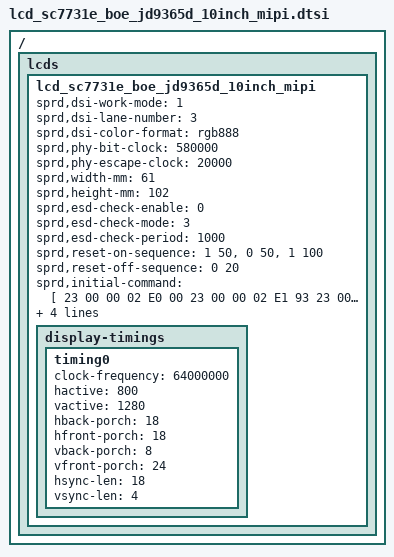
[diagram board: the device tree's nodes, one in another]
/ { lcds {
	lcd_sc7731e_boe_jd9365d_10inch_mipi: lcd_sc7731e_boe_jd9365d_10inch_mipi {

		sprd,dsi-work-mode = <1>;
		sprd,dsi-lane-number = <3>;
		sprd,dsi-color-format = "rgb888";

		sprd,phy-bit-clock = <580000>;
		sprd,phy-escape-clock = <20000>;

		sprd,width-mm = <61>;
		sprd,height-mm = <102>;

		sprd,esd-check-enable = <0>;
		sprd,esd-check-mode = <3>;
		sprd,esd-check-period = <1000>;
		/*sprd,esd-check-register = <0x0A>;*/
		/*sprd,esd-check-value = <0x9C>;*/

		sprd,reset-on-sequence = <1 50>, <0 50>, <1 100>;
		sprd,reset-off-sequence = <0 20>;

		sprd,initial-command = [
	 23 00 00 02 E0 00
		//--- PASSWORD  ----//
		 23 00 00 02 E1 93
		 23 00 00 02 E2 65
		 23 00 00 02 E3 F8
		 23 00 00 02 80 02// 03:4-LANE; 02:3-LANE; 01:2-LANE

		//--- Page1  ----//
		 23 00 00 02 E0 01

		// 23 00 00 02 4A 30 //bist mode

		//Set VCOM
		 23 00 00 02 00 00
		 23 00 00 02 01 66
		 23 00 00 02 0E 01	//LEDON output VCSW2
		//Set Gamma Power VGMPVGMNVGSPVGSN
		 23 00 00 02 17 00
		 23 00 00 02 18 AF//4.3V
		 23 00 00 02 19 01//0.3V
		 23 00 00 02 1A 00//
		 23 00 00 02 1B AF//4.3V
		 23 00 00 02 1C 01//0.3V               
		//Set Gate Power
		 23 00 00 02 1F 3E     //VGH_R  = 15V                       
		 23 00 00 02 20 28     //VGL_R  = -12V                      
		 23 00 00 02 21 28     //VGL_R2 = -12V                      
		 23 00 00 02 22 7E     //PA[6]=1 PA[5]=1 PA[4]=1 PA[0]=0 
		//SETPANEL
		 23 00 00 02 35 26	//ASP=0110
		//SETPANEL
		 23 00 00 02 37 09	//SS=1BGR=1
		//SET RGBCYC
		 23 00 00 02 38 04	//JDT=100 column inversion
		 23 00 00 02 39 00	//RGB_N_EQ1 12
		 23 00 00 02 3A 01	//RGB_N_EQ2 18
		 23 00 00 02 3C 7C	//SET EQ3 for TE_H
		 23 00 00 02 3D FF	//SET CHGEN_ON 
		 23 00 00 02 3E FF	//SET CHGEN_OFF 
		 23 00 00 02 3F 7F	//SET CHGEN_OFF2
		//Set TCON
		 23 00 00 02 40 06	//RSO=800 RGB
		 23 00 00 02 41 A0	//LN=640->1280 line
		 23 00 00 02 42 81	//SLT
		 23 00 00 02 43 08	//VFP=8
		 23 00 00 02 44 0B	//VBP=12
		 23 00 00 02 45 28  //HBP=40
		//--- power voltage  ----//
		 23 00 00 02 55 01	//DCDCM=0001 JD PWR_IC
		 23 00 00 02 56 01
		 23 00 00 02 57 69
		 23 00 00 02 58 0A
		 23 00 00 02 59 0A	//VCL = -2.5V
		 23 00 00 02 5A 29	//VGH = 15.2V
		 23 00 00 02 5B 15	//VGL = -11.2V
		//--- Gamma  ----//
		 23 00 00 02 5D 7C              
		 23 00 00 02 5E 65      
		 23 00 00 02 5F 55    
		 23 00 00 02 60 47    
		 23 00 00 02 61 43    
		 23 00 00 02 62 32    
		 23 00 00 02 63 34    
		 23 00 00 02 64 1C    
		 23 00 00 02 65 33    
		 23 00 00 02 66 31    
		 23 00 00 02 67 30    
		 23 00 00 02 68 4E    
		 23 00 00 02 69 3C    
		 23 00 00 02 6A 44    
		 23 00 00 02 6B 35    
		 23 00 00 02 6C 31    
		 23 00 00 02 6D 23    
		 23 00 00 02 6E 11    
		 23 00 00 02 6F 00    
		 23 00 00 02 70 7C    
		 23 00 00 02 71 65    
		 23 00 00 02 72 55    
		 23 00 00 02 73 47    
		 23 00 00 02 74 43    
		 23 00 00 02 75 32    
		 23 00 00 02 76 34    
		 23 00 00 02 77 1C    
		 23 00 00 02 78 33    
		 23 00 00 02 79 31    
		 23 00 00 02 7A 30    
		 23 00 00 02 7B 4E    
		 23 00 00 02 7C 3C    
		 23 00 00 02 7D 44    
		 23 00 00 02 7E 35    
		 23 00 00 02 7F 31    
		 23 00 00 02 80 23    
		 23 00 00 02 81 11    
		 23 00 00 02 82 00                                    
		//Page2 for GIP                                      
		 23 00 00 02 E0 02                                
		//GIP_L Pin mapping                                   
		 23 00 00 02 00 1E//1  VDS                        
		 23 00 00 02 01 1E//2  VDS                        
		 23 00 00 02 02 41//3  STV2                       
		 23 00 00 02 03 41//4  STV2                       
		 23 00 00 02 04 43//5  STV4                       
		 23 00 00 02 05 43//6  STV4                       
		 23 00 00 02 06 1F//7  VSD                        
		 23 00 00 02 07 1F//8  VSD                        
		 23 00 00 02 08 35//9  GCL                        
		 23 00 00 02 09 1F//10                            
		 23 00 00 02 0A 15//11 GCH                        
		 23 00 00 02 0B 15//12 GCH                        
		 23 00 00 02 0C 1F//13                            
		 23 00 00 02 0D 47//14 CLK8                       
		 23 00 00 02 0E 47//15 CLK8                       
		 23 00 00 02 0F 45//16 CLK6                       
		 23 00 00 02 10 45//17 CLK6                       
		 23 00 00 02 11 4B//18 CLK4                       
		 23 00 00 02 12 4B//19 CLK4                       
		 23 00 00 02 13 49//20 CLK2                       
		 23 00 00 02 14 49//21 CLK2                       
		 23 00 00 02 15 1F//22 VGL                                                                             
		//GIP_R Pin mapping                                   
		 23 00 00 02 16 1E//1  VDS                 
		 23 00 00 02 17 1E//2  VDS                
		 23 00 00 02 18 40//3  STV1               
		 23 00 00 02 19 40//4  STV1               
		 23 00 00 02 1A 42//5  STV3               
		 23 00 00 02 1B 42//6  STV3               
		 23 00 00 02 1C 1F//7  VSD                
		 23 00 00 02 1D 1F//8  VSD                
		 23 00 00 02 1E 35//9  GCL                
		 23 00 00 02 1F 1F//10                    
		 23 00 00 02 20 15//11 GCH                
		 23 00 00 02 21 15//12 GCH                
		 23 00 00 02 22 1f//13                    
		 23 00 00 02 23 46//14 CLK7               
		 23 00 00 02 24 46//15 CLK7               
		 23 00 00 02 25 44//16 CLK5               
		 23 00 00 02 26 44//17 CLK5               
		 23 00 00 02 27 4A//18 CLK3               
		 23 00 00 02 28 4A//19 CLK3               
		 23 00 00 02 29 48//20 CLK1               
		 23 00 00 02 2A 48//21 CLK1               
		 23 00 00 02 2B 1f//22 VGL 
		//GIP Timing  
		 23 00 00 02 58 40 
		 23 00 00 02 5B 30 //STV_NUMSTV_S0
		 23 00 00 02 5C 03 //STV_S0
		 23 00 00 02 5D 30 //STV_W / S1
		 23 00 00 02 5E 01 //STV_S2
		 23 00 00 02 5F 02 //STV_S3
		 23 00 00 02 63 14 //SETV_ON  
		 23 00 00 02 64 6A //SETV_OFF 
		 23 00 00 02 67 73 
		 23 00 00 02 68 05 
		 23 00 00 02 69 14 
		 23 00 00 02 6A 6A 
		 23 00 00 02 6B 08 //Dummy clk
		 23 00 00 02 6C 00 
		 23 00 00 02 6D 00 
		 23 00 00 02 6E 00 
		 23 00 00 02 6F 88 
		 23 00 00 02 77 DD 
		 23 00 00 02 79 0E// 0C 
		 23 00 00 02 7A 03// 04
		 23 00 00 02 7D 14 
		 23 00 00 02 7E 6A 

		//Page4
		 23 00 00 02 E0 04
		 23 00 00 02 2B 2B
		 23 00 00 02 2E 44
		 23 00 00 02 09 11
		 23 00 00 02 2D 03
		 23 00 00 02 0E 48

		//Page0
		 23 00 00 02 E0 00
		 23 00 00 02 E6 02
		 23 00 00 02 E7 02
		//SLP OUT
		 23 78 00 02 11 00
         23 64 00 02 29 00  	// DSPON
			];
		sprd,sleep-in-command = [
			13 0A 00 01 28
			13 78 00 01 10
			];
		sprd,sleep-out-command = [
			13 78 00 01 11
			13 64 00 01 29
			];

		display-timings {
			timing0 {
			clock-frequency = <64000000>;
			hactive = <800>;
			vactive = <1280>;
			hback-porch = <18>;
			hfront-porch = <18>;
			vback-porch = <8>;
			vfront-porch = <24>;
			hsync-len = <18>;
			vsync-len = <4>;
			};
		};
	};
};};

